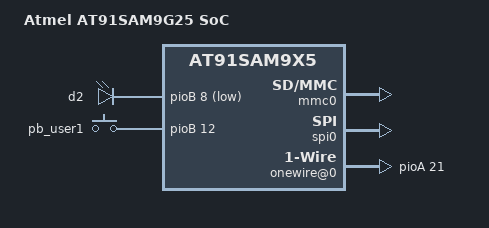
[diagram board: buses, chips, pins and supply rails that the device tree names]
/*
 * at91sam9g25.dtsi - Device Tree Include file for AT91SAM9G25 SoC
 *
 * Copyright (C) 2012 Jean-Christophe PLAGNIOL-VILLARD <plagnioj@jcrosoft.com>
 *
 * Licensed under GPLv2.
 */

/include/ "at91sam9x5.dtsi"

/ {
	model = "Atmel AT91SAM9G25 SoC";
	compatible = "atmel, at91sam9g25, atmel,at91sam9x5";


	ahb {
		apb {
			pinctrl@fffff400 {
				atmel,mux-mask = <
				      /*    A         B          C     */
				       0xffffffff 0xffe0399f 0xc000001c  /* pioA */
				       0x0007ffff 0x8000fe3f 0x00000000  /* pioB */
				       0x80000000 0x07c0ffff 0xb83fffff  /* pioC */
				       0x003fffff 0x003f8000 0x00000000  /* pioD */
				      >;
			};
			
			pinctrl@fffff400 {
				w1_0 {          
					pinctrl_w1_0: w1_0-0 {            
						atmel,pins = <0 21 0x0 0x1>; /* PA21 PIO, pull-up */          
					};        
				};
			};

			mmc0: mmc@f0008000 {
				pinctrl-0 = <&pinctrl_mmc0_clk_cmd_dat0 &pinctrl_mmc0_dat1_3 &pinctrl_mmc0_cd>;
				status = "okay";
				slot@0 {
					reg = <0>;
					bus-width = <4>;
					cd-gpios = <&pioA 4 0>;
				};
			};

			spi0: spi@f0000000 {
				status = "okay";        

				/*
				device@0 {          
					compatible = "spidev";          // spi-max-frequency = <50000000>;  // 50 MHz    
					spi-max-frequency = <5000000>;	    // 5 MHz          
					reg = <0>;        
				};
				*/
				/*
				st7735_lcd{
					compatible = "st7735";          

					spi-max-frequency = <30000000>;		// 30 MHz    
					reg = <0>;        
					backlight-gpios = <&pioB 11 0>;
					cd-gpios = <&pioB 12 0>;
					rst-gpios = <&pioB 13 0>;
					//spi-cpha;							//rise edge tranfer data  both mode0 and mode3 are ok
					//spi-cpol;
				};
				*/
			};
		};
	};

	leds {
		compatible = "gpio-leds";

		d2 {
			label = "d2";
			gpios = <&pioB 8 1>;
			linux,default-trigger = "heartbeat";
		};
	};

	gpio_keys {
		compatible = "gpio-keys";
		#address-cells = <1>;
		#size-cells = <0>;

		pb_user1 {
			label = "pb_user1";
			gpios = <&pioB 12 0>;
			linux,code = <0x100>;
			gpio-key,wakeup;
		};
	};

	onewire@0 {    
		compatible = "w1-gpio";    
		gpios = <&pioA 21 0>;    
		pinctrl-names = "default";    
		pinctrl-0 = <&pinctrl_w1_0>;  
		status = "okay";
	};
};
